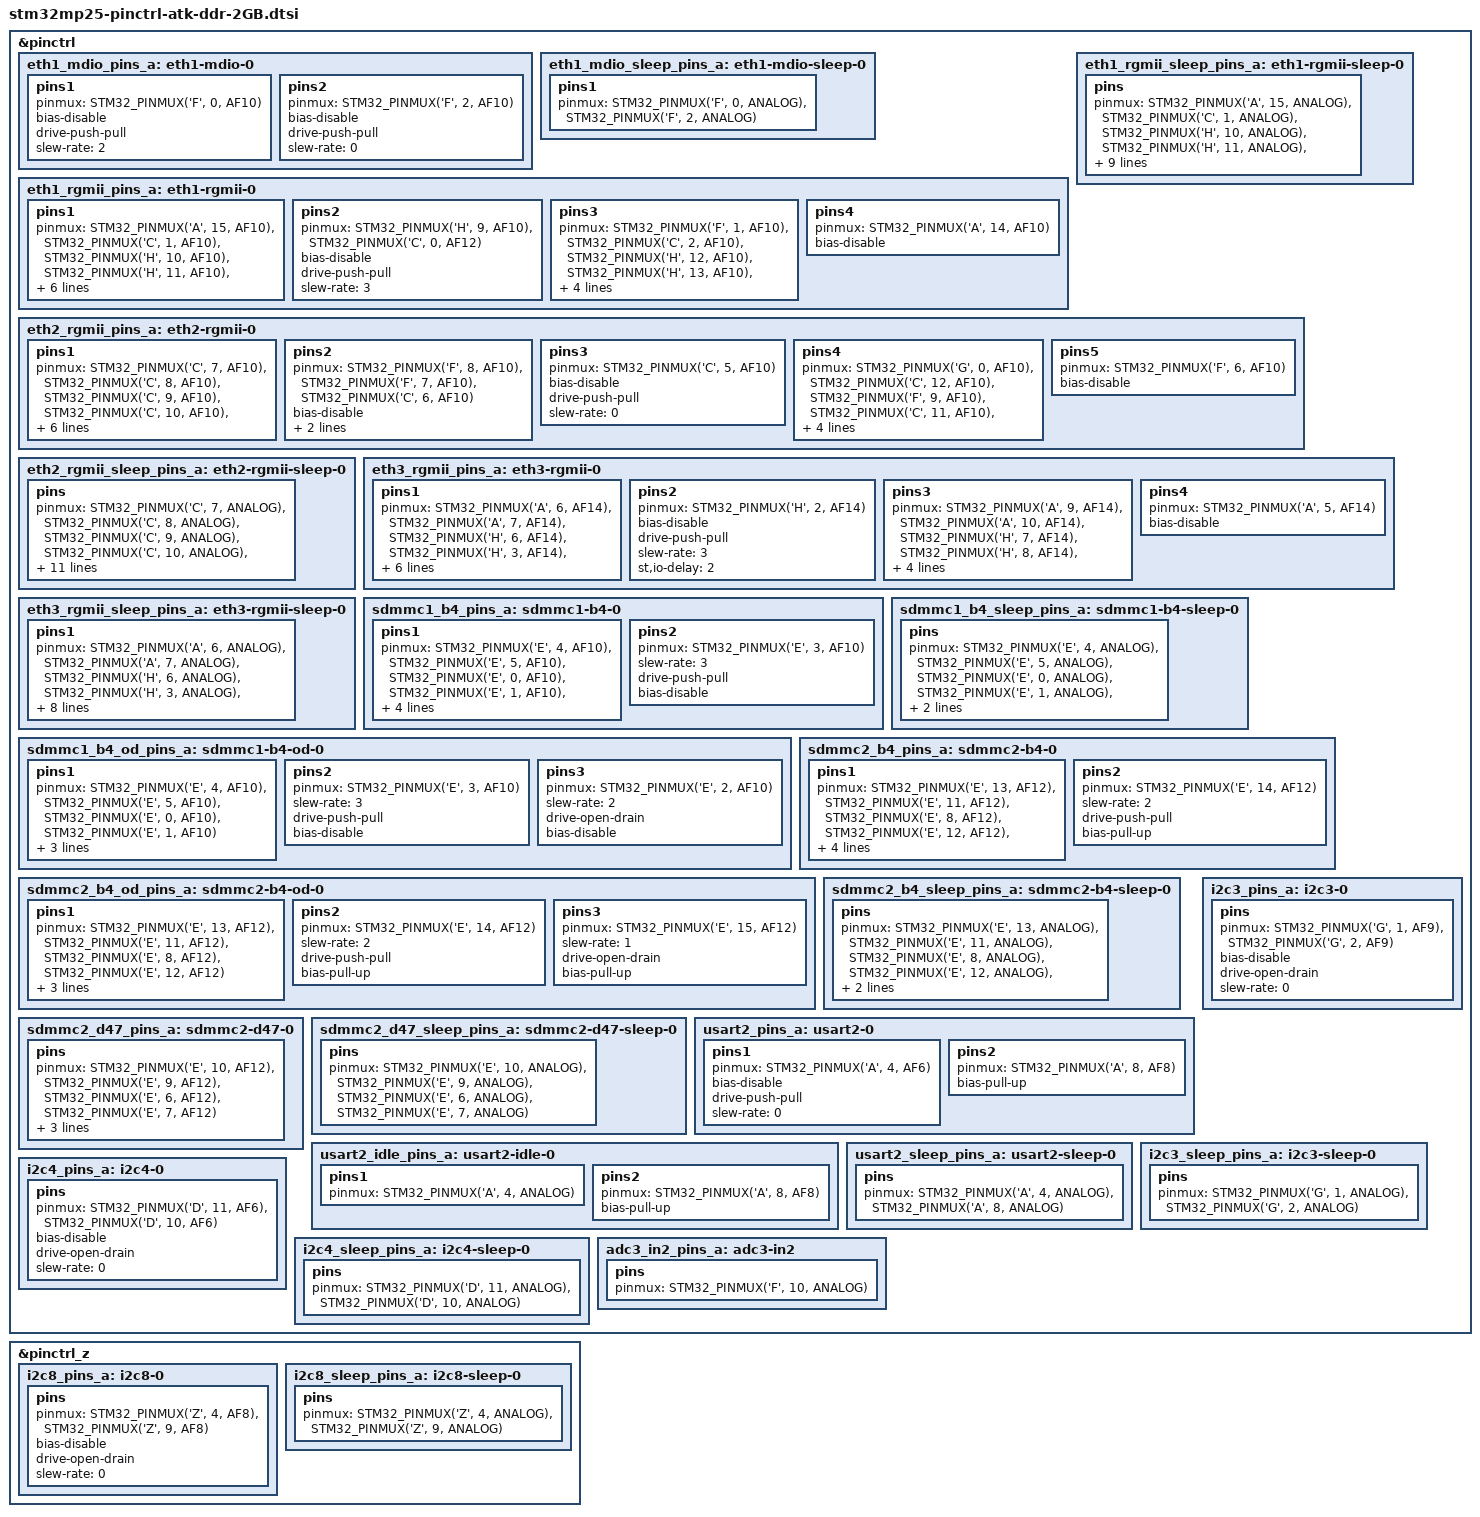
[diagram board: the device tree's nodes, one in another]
#include <dt-bindings/pinctrl/stm32-pinfunc.h>

&pinctrl {
	eth1_mdio_pins_a: eth1-mdio-0 {
		pins1 {
			pinmux = <STM32_PINMUX('F', 0, AF10)>; /* ETH_MDC */
			bias-disable;
			drive-push-pull;
			slew-rate = <2>;
		};
		pins2 {
			pinmux = <STM32_PINMUX('F', 2, AF10)>; /* ETH_MDIO */
			bias-disable;
			drive-push-pull;
			slew-rate = <0>;
		};
	};

	eth1_mdio_sleep_pins_a: eth1-mdio-sleep-0 {
		pins1 {
			pinmux = <STM32_PINMUX('F', 0, ANALOG)>, /* ETH_MDC */
				 <STM32_PINMUX('F', 2, ANALOG)>; /* ETH_MDIO */
		};
	};

	eth1_rgmii_pins_a: eth1-rgmii-0 {
		pins1 {
			pinmux = <STM32_PINMUX('A', 15, AF10)>, /* ETH_RGMII_TXD0 */
				 <STM32_PINMUX('C', 1, AF10)>, /* ETH_RGMII_TXD1 */
				 <STM32_PINMUX('H', 10, AF10)>, /* ETH_RGMII_TXD2 */
				 <STM32_PINMUX('H', 11, AF10)>, /* ETH_RGMII_TXD3 */
				 <STM32_PINMUX('A', 13, AF10)>; /* ETH_RGMII_TX_CTL */
			bias-disable;
			drive-push-pull;
			slew-rate = <3>;
			st,io-retime = <1>;
			st,io-clk-edge = <1>;
		};
		pins2 {
			pinmux = <STM32_PINMUX('H', 9, AF10)>, /* ETH_RGMII_CLK125 */
				 <STM32_PINMUX('C', 0, AF12)>; /* ETH_RGMII_GTX_CLK */
			bias-disable;
			drive-push-pull;
			slew-rate = <3>;
		};
		pins3 {
			pinmux = <STM32_PINMUX('F', 1, AF10)>, /* ETH_RGMII_RXD0 */
				 <STM32_PINMUX('C', 2, AF10)>, /* ETH_RGMII_RXD1 */
				 <STM32_PINMUX('H', 12, AF10)>, /* ETH_RGMII_RXD2 */
				 <STM32_PINMUX('H', 13, AF10)>, /* ETH_RGMII_RXD3 */
				 <STM32_PINMUX('A', 11, AF10)>; /* ETH_RGMII_RX_CTL */
			bias-disable;
			st,io-retime = <1>;
			st,io-clk-edge = <1>;
		};
		pins4 {
			pinmux = <STM32_PINMUX('A', 14, AF10)>; /* ETH_RGMII_RX_CLK */
			bias-disable;
		};
	};

	eth1_rgmii_sleep_pins_a: eth1-rgmii-sleep-0 {
		pins {
			pinmux = <STM32_PINMUX('A', 15, ANALOG)>, /* ETH_RGMII_TXD0 */
				 <STM32_PINMUX('C', 1, ANALOG)>, /* ETH_RGMII_TXD1 */
				 <STM32_PINMUX('H', 10, ANALOG)>, /* ETH_RGMII_TXD2 */
				 <STM32_PINMUX('H', 11, ANALOG)>, /* ETH_RGMII_TXD3 */
				 <STM32_PINMUX('A', 13, ANALOG)>, /* ETH_RGMII_TX_CTL */
				 <STM32_PINMUX('H', 9, ANALOG)>, /* ETH_RGMII_CLK125 */
				 <STM32_PINMUX('C', 0, ANALOG)>, /* ETH_RGMII_GTX_CLK */
				 <STM32_PINMUX('F', 1, ANALOG)>, /* ETH_RGMII_RXD0 */
				 <STM32_PINMUX('C', 2, ANALOG)>, /* ETH_RGMII_RXD1 */
				 <STM32_PINMUX('H', 12, ANALOG)>, /* ETH_RGMII_RXD2 */
				 <STM32_PINMUX('H', 13, ANALOG)>, /* ETH_RGMII_RXD3 */
				 <STM32_PINMUX('A', 11, ANALOG)>, /* ETH_RGMII_RX_CTL */
				 <STM32_PINMUX('A', 14, ANALOG)>; /* ETH_RGMII_RX_CLK */
		};
	};

	eth2_rgmii_pins_a: eth2-rgmii-0 {
		pins1 {
			pinmux = <STM32_PINMUX('C', 7, AF10)>, /* ETH_RGMII_TXD0 */
				 <STM32_PINMUX('C', 8, AF10)>, /* ETH_RGMII_TXD1 */
				 <STM32_PINMUX('C', 9, AF10)>, /* ETH_RGMII_TXD2 */
				 <STM32_PINMUX('C', 10, AF10)>, /* ETH_RGMII_TXD3 */
				 <STM32_PINMUX('C', 4, AF10)>; /* ETH_RGMII_TX_CTL */
			bias-disable;
			drive-push-pull;
			slew-rate = <3>;
			st,io-retime = <1>;
			st,io-clk-edge = <1>;
		};
		pins2 {
			pinmux = <STM32_PINMUX('F', 8, AF10)>, /* ETH_RGMII_CLK125 */
				 <STM32_PINMUX('F', 7, AF10)>, /* ETH_RGMII_GTX_CLK */
				 <STM32_PINMUX('C', 6, AF10)>; /* ETH_MDC */
			bias-disable;
			drive-push-pull;
			slew-rate = <3>;
		};
		pins3 {
			pinmux = <STM32_PINMUX('C', 5, AF10)>; /* ETH_MDIO */
			bias-disable;
			drive-push-pull;
			slew-rate = <0>;
		};
		pins4 {
			pinmux = <STM32_PINMUX('G', 0, AF10)>, /* ETH_RGMII_RXD0 */
				 <STM32_PINMUX('C', 12, AF10)>, /* ETH_RGMII_RXD1 */
				 <STM32_PINMUX('F', 9, AF10)>, /* ETH_RGMII_RXD2 */
				 <STM32_PINMUX('C', 11, AF10)>, /* ETH_RGMII_RXD3 */
				 <STM32_PINMUX('C', 3, AF10)>; /* ETH_RGMII_RX_CTL */
			bias-disable;
			st,io-retime = <1>;
			st,io-clk-edge = <1>;
		};
		pins5 {
			pinmux = <STM32_PINMUX('F', 6, AF10)>; /* ETH_RGMII_RX_CLK */
			bias-disable;
		};
	};

	eth2_rgmii_sleep_pins_a: eth2-rgmii-sleep-0 {
		pins {
			pinmux = <STM32_PINMUX('C', 7, ANALOG)>, /* ETH_RGMII_TXD0 */
				 <STM32_PINMUX('C', 8, ANALOG)>, /* ETH_RGMII_TXD1 */
				 <STM32_PINMUX('C', 9, ANALOG)>, /* ETH_RGMII_TXD2 */
				 <STM32_PINMUX('C', 10, ANALOG)>, /* ETH_RGMII_TXD3 */
				 <STM32_PINMUX('C', 4, ANALOG)>, /* ETH_RGMII_TX_CTL */
				 <STM32_PINMUX('F', 8, ANALOG)>, /* ETH_RGMII_CLK125 */
				 <STM32_PINMUX('F', 7, ANALOG)>, /* ETH_RGMII_GTX_CLK */
				 <STM32_PINMUX('C', 6, ANALOG)>, /* ETH_MDC */
				 <STM32_PINMUX('C', 5, ANALOG)>, /* ETH_MDIO */
				 <STM32_PINMUX('G', 0, ANALOG)>, /* ETH_RGMII_RXD0 */
				 <STM32_PINMUX('C', 12, ANALOG)>, /* ETH_RGMII_RXD1 */
				 <STM32_PINMUX('F', 9, ANALOG)>, /* ETH_RGMII_RXD2 */
				 <STM32_PINMUX('C', 11, ANALOG)>, /* ETH_RGMII_RXD3 */
				 <STM32_PINMUX('C', 3, ANALOG)>, /* ETH_RGMII_RX_CTL */
				 <STM32_PINMUX('F', 6, ANALOG)>; /* ETH_RGMII_RX_CLK */
		};
	};

	eth3_rgmii_pins_a: eth3-rgmii-0 {
		pins1 {
			pinmux = <STM32_PINMUX('A', 6, AF14)>, /* ETH_RGMII_TXD0 */
				 <STM32_PINMUX('A', 7, AF14)>, /* ETH_RGMII_TXD1 */
				 <STM32_PINMUX('H', 6, AF14)>, /* ETH_RGMII_TXD2 */
				 <STM32_PINMUX('H', 3, AF14)>, /* ETH_RGMII_TXD3 */
				 <STM32_PINMUX('A', 3, AF14)>; /* ETH_RGMII_TX_CTL */
			bias-disable;
			drive-push-pull;
			slew-rate = <3>;
			st,io-retime = <1>;
			st,io-clk-edge = <1>;
		};
		pins2 {
			pinmux = <STM32_PINMUX('H', 2, AF14)>; /* ETH_RGMII_GTX_CLK */
			bias-disable;
			drive-push-pull;
			slew-rate = <3>;
			st,io-delay = <2>;
		};
		pins3 {
			pinmux = <STM32_PINMUX('A', 9, AF14)>, /* ETH_RGMII_RXD0 */
				 <STM32_PINMUX('A', 10, AF14)>, /* ETH_RGMII_RXD1 */
				 <STM32_PINMUX('H', 7, AF14)>, /* ETH_RGMII_RXD2 */
				 <STM32_PINMUX('H', 8, AF14)>, /* ETH_RGMII_RXD3 */
				 <STM32_PINMUX('A', 2, AF14)>; /* ETH_RGMII_RX_CTL */
			bias-disable;
			st,io-retime = <1>;
			st,io-clk-edge = <1>;
		};
		pins4 {
			pinmux = <STM32_PINMUX('A', 5, AF14)>; /* ETH_RGMII_RX_CLK */
			bias-disable;
		};
	};

	eth3_rgmii_sleep_pins_a: eth3-rgmii-sleep-0 {
		pins1 {
			pinmux = <STM32_PINMUX('A', 6, ANALOG)>, /* ETH_RGMII_TXD0 */
				 <STM32_PINMUX('A', 7, ANALOG)>, /* ETH_RGMII_TXD1 */
				 <STM32_PINMUX('H', 6, ANALOG)>, /* ETH_RGMII_TXD2 */
				 <STM32_PINMUX('H', 3, ANALOG)>, /* ETH_RGMII_TXD3 */
				 <STM32_PINMUX('A', 3, ANALOG)>, /* ETH_RGMII_TX_CTL */
				 <STM32_PINMUX('H', 2, ANALOG)>, /* ETH_RGMII_GTX_CLK */
				 <STM32_PINMUX('A', 9, ANALOG)>, /* ETH_RGMII_RXD0 */
				 <STM32_PINMUX('A', 10, ANALOG)>, /* ETH_RGMII_RXD1 */
				 <STM32_PINMUX('H', 7, ANALOG)>, /* ETH_RGMII_RXD2 */
				 <STM32_PINMUX('H', 8, ANALOG)>, /* ETH_RGMII_RXD3 */
				 <STM32_PINMUX('A', 2, ANALOG)>, /* ETH_RGMII_RX_CTL */
				 <STM32_PINMUX('A', 5, ANALOG)>; /* ETH_RGMII_RX_CLK */
		};
	};

	sdmmc1_b4_pins_a: sdmmc1-b4-0 {
		pins1 {
			pinmux = <STM32_PINMUX('E', 4, AF10)>, /* SDMMC1_D0 */
				 <STM32_PINMUX('E', 5, AF10)>, /* SDMMC1_D1 */
				 <STM32_PINMUX('E', 0, AF10)>, /* SDMMC1_D2 */
				 <STM32_PINMUX('E', 1, AF10)>, /* SDMMC1_D3 */
				 <STM32_PINMUX('E', 2, AF10)>; /* SDMMC1_CMD */
			slew-rate = <2>;
			drive-push-pull;
			bias-disable;
		};
		pins2 {
			pinmux = <STM32_PINMUX('E', 3, AF10)>; /* SDMMC1_CK */
			slew-rate = <3>;
			drive-push-pull;
			bias-disable;
		};
	};

	sdmmc1_b4_od_pins_a: sdmmc1-b4-od-0 {
		pins1 {
			pinmux = <STM32_PINMUX('E', 4, AF10)>, /* SDMMC1_D0 */
				 <STM32_PINMUX('E', 5, AF10)>, /* SDMMC1_D1 */
				 <STM32_PINMUX('E', 0, AF10)>, /* SDMMC1_D2 */
				 <STM32_PINMUX('E', 1, AF10)>; /* SDMMC1_D3 */
			slew-rate = <2>;
			drive-push-pull;
			bias-disable;
		};
		pins2 {
			pinmux = <STM32_PINMUX('E', 3, AF10)>; /* SDMMC1_CK */
			slew-rate = <3>;
			drive-push-pull;
			bias-disable;
		};
		pins3 {
			pinmux = <STM32_PINMUX('E', 2, AF10)>; /* SDMMC1_CMD */
			slew-rate = <2>;
			drive-open-drain;
			bias-disable;
		};
	};

	sdmmc1_b4_sleep_pins_a: sdmmc1-b4-sleep-0 {
		pins {
			pinmux = <STM32_PINMUX('E', 4, ANALOG)>, /* SDMMC1_D0 */
				 <STM32_PINMUX('E', 5, ANALOG)>, /* SDMMC1_D1 */
				 <STM32_PINMUX('E', 0, ANALOG)>, /* SDMMC1_D2 */
				 <STM32_PINMUX('E', 1, ANALOG)>, /* SDMMC1_D3 */
				 <STM32_PINMUX('E', 3, ANALOG)>, /* SDMMC1_CK */
				 <STM32_PINMUX('E', 2, ANALOG)>; /* SDMMC1_CMD */
		};
	};

	sdmmc2_b4_pins_a: sdmmc2-b4-0 {
		pins1 {
			pinmux = <STM32_PINMUX('E', 13, AF12)>, /* SDMMC2_D0 */
				 <STM32_PINMUX('E', 11, AF12)>, /* SDMMC2_D1 */
				 <STM32_PINMUX('E', 8, AF12)>, /* SDMMC2_D2 */
				 <STM32_PINMUX('E', 12, AF12)>, /* SDMMC2_D3 */
				 <STM32_PINMUX('E', 15, AF12)>; /* SDMMC2_CMD */
			slew-rate = <1>;
			drive-push-pull;
			bias-pull-up;
		};
		pins2 {
			pinmux = <STM32_PINMUX('E', 14, AF12)>; /* SDMMC2_CK */
			slew-rate = <2>;
			drive-push-pull;
			bias-pull-up;
		};
	};

	sdmmc2_b4_od_pins_a: sdmmc2-b4-od-0 {
		pins1 {
			pinmux = <STM32_PINMUX('E', 13, AF12)>, /* SDMMC2_D0 */
				 <STM32_PINMUX('E', 11, AF12)>, /* SDMMC2_D1 */
				 <STM32_PINMUX('E', 8, AF12)>, /* SDMMC2_D2 */
				 <STM32_PINMUX('E', 12, AF12)>; /* SDMMC2_D3 */
			slew-rate = <1>;
			drive-push-pull;
			bias-pull-up;
		};
		pins2 {
			pinmux = <STM32_PINMUX('E', 14, AF12)>; /* SDMMC2_CK */
			slew-rate = <2>;
			drive-push-pull;
			bias-pull-up;
		};
		pins3 {
			pinmux = <STM32_PINMUX('E', 15, AF12)>; /* SDMMC2_CMD */
			slew-rate = <1>;
			drive-open-drain;
			bias-pull-up;
		};
	};

	sdmmc2_b4_sleep_pins_a: sdmmc2-b4-sleep-0 {
		pins {
			pinmux = <STM32_PINMUX('E', 13, ANALOG)>, /* SDMMC2_D0 */
				 <STM32_PINMUX('E', 11, ANALOG)>, /* SDMMC2_D1 */
				 <STM32_PINMUX('E', 8, ANALOG)>, /* SDMMC2_D2 */
				 <STM32_PINMUX('E', 12, ANALOG)>, /* SDMMC2_D3 */
				 <STM32_PINMUX('E', 14, ANALOG)>, /* SDMMC2_CK */
				 <STM32_PINMUX('E', 15, ANALOG)>; /* SDMMC2_CMD */
		};
	};

	sdmmc2_d47_pins_a: sdmmc2-d47-0 {
		pins {
			pinmux = <STM32_PINMUX('E', 10, AF12)>, /* SDMMC2_D4 */
				 <STM32_PINMUX('E', 9, AF12)>, /* SDMMC2_D5 */
				 <STM32_PINMUX('E', 6, AF12)>, /* SDMMC2_D6 */
				 <STM32_PINMUX('E', 7, AF12)>; /* SDMMC2_D7 */
			slew-rate = <1>;
			drive-push-pull;
			bias-pull-up;
		};
	};

	sdmmc2_d47_sleep_pins_a: sdmmc2-d47-sleep-0 {
		pins {
			pinmux = <STM32_PINMUX('E', 10, ANALOG)>, /* SDMMC2_D4 */
				 <STM32_PINMUX('E', 9, ANALOG)>, /* SDMMC2_D5 */
				 <STM32_PINMUX('E', 6, ANALOG)>, /* SDMMC2_D6 */
				 <STM32_PINMUX('E', 7, ANALOG)>; /* SDMMC2_D7 */
		};
	};

	usart2_pins_a: usart2-0 {
		pins1 {
			pinmux = <STM32_PINMUX('A', 4, AF6)>; /* USART2_TX */
			bias-disable;
			drive-push-pull;
			slew-rate = <0>;
		};
		pins2 {
			pinmux = <STM32_PINMUX('A', 8, AF8)>; /* USART2_RX */
			bias-pull-up;
		};
	};

	usart2_idle_pins_a: usart2-idle-0 {
		pins1 {
			pinmux = <STM32_PINMUX('A', 4, ANALOG)>; /* USART2_TX */
		};
		pins2 {
			pinmux = <STM32_PINMUX('A', 8, AF8)>; /* USART2_RX */
			bias-pull-up;
		};
	};

	usart2_sleep_pins_a: usart2-sleep-0 {
		pins {
			pinmux = <STM32_PINMUX('A', 4, ANALOG)>, /* USART2_TX */
				 <STM32_PINMUX('A', 8, ANALOG)>; /* USART2_RX */
		};
	};

	i2c3_pins_a: i2c3-0 {
		pins {
			pinmux = <STM32_PINMUX('G', 1, AF9)>, /* I2C3_SCL */
				 <STM32_PINMUX('G', 2, AF9)>; /* I2C3_SDA */
			bias-disable;
			drive-open-drain;
			slew-rate = <0>;
		};
	};

	i2c3_sleep_pins_a: i2c3-sleep-0 {
		pins {
			pinmux = <STM32_PINMUX('G', 1, ANALOG)>, /* I2C3_SCL */
				 <STM32_PINMUX('G', 2, ANALOG)>; /* I2C3_SDA */
		};
	};

	i2c4_pins_a: i2c4-0 {
		pins {
			pinmux = <STM32_PINMUX('D', 11, AF6)>, /* I2C4_SCL */
				 <STM32_PINMUX('D', 10, AF6)>; /* I2C4_SDA */
			bias-disable;
			drive-open-drain;
			slew-rate = <0>;
		};
	};

	i2c4_sleep_pins_a: i2c4-sleep-0 {
		pins {
			pinmux = <STM32_PINMUX('D', 11, ANALOG)>, /* I2C4_SCL */
				 <STM32_PINMUX('D', 10, ANALOG)>; /* I2C4_SDA */
		};
	};
	
	adc3_in2_pins_a: adc3-in2 {
		pins {
			pinmux = <STM32_PINMUX('F', 10, ANALOG)>;
		};
	};
};

&pinctrl_z {
	i2c8_pins_a: i2c8-0 {
		pins {
			pinmux = <STM32_PINMUX('Z', 4, AF8)>, /* I2C8_SCL */
				 <STM32_PINMUX('Z', 9, AF8)>; /* I2C8_SDA */
			bias-disable;
			drive-open-drain;
			slew-rate = <0>;
		};
	};

	i2c8_sleep_pins_a: i2c8-sleep-0 {
		pins {
			pinmux = <STM32_PINMUX('Z', 4, ANALOG)>, /* I2C8_SCL */
				 <STM32_PINMUX('Z', 9, ANALOG)>; /* I2C8_SDA */
		};
	};
};
